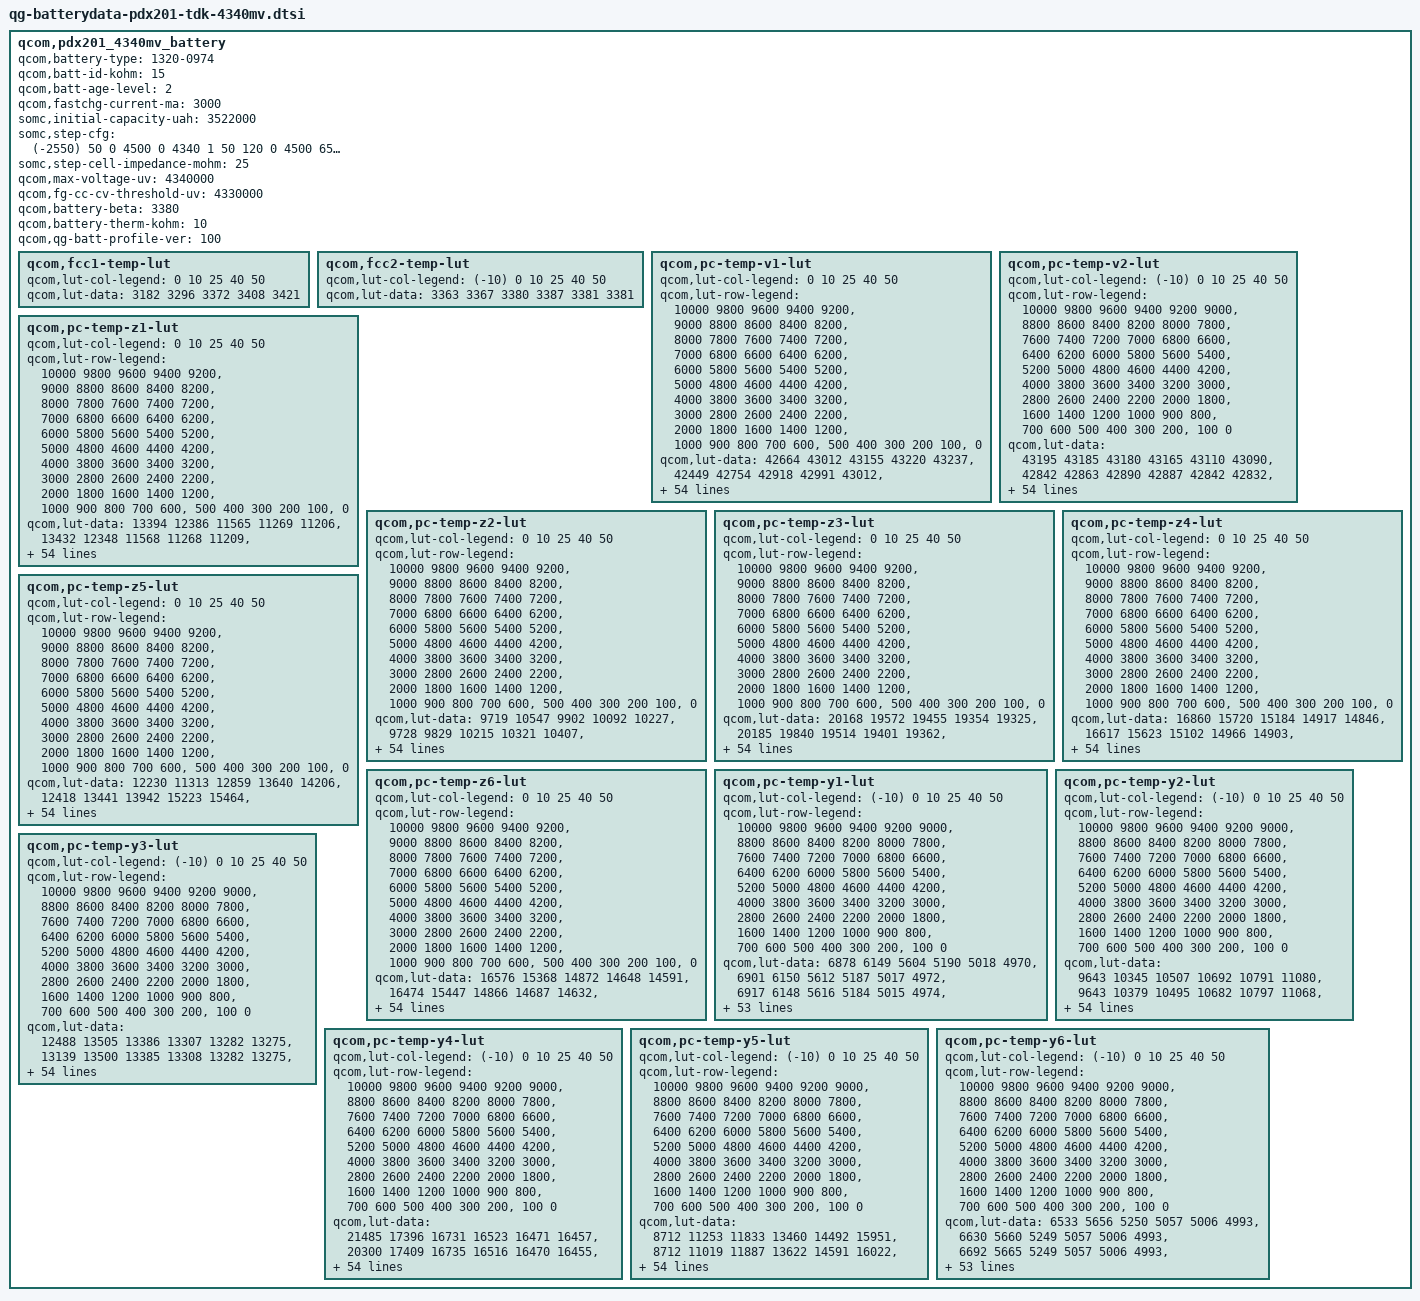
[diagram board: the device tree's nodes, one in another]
// SPDX-License-Identifier: GPL-2.0-only
/*
 * Copyright (c) 2019, The Linux Foundation. All rights reserved.
 */

qcom,pdx201_4340mv_battery {
	/* Added or Modified by SOMC */
	qcom,battery-type = "1320-0974";
	qcom,batt-id-kohm = <15>;
	qcom,batt-age-level = <2>;
	qcom,fastchg-current-ma = <3000>;
	somc,initial-capacity-uah = <3522000>;
	somc,step-cfg = <
		(-2550) 50    0 4500    0 4340 1
		   50  120    0 4500  650 4340 2
		  120  200    0 4100 2050 4340 3
		  120  200 4100 4200 1550 4340 3
		  120  200 4200 4300 1350 4340 3
		  120  200 4300 4500 1000 4340 3
		  200  450    0 4150 3000 4340 3
		  200  450 4150 4200 2400 4340 3
		  200  450 4200 4300 1700 4340 3
		  200  450 4300 4500 1000 4340 3
		  450  550    0 4500 1000 4200 4
		  550 2550    0 4500    0 4200 5
	>;
	somc,step-cell-impedance-mohm = <25>;

	/* Prepared by Qualcomm */
	/* 4176713_SoMC_Amuro2_3389mAh_averaged_MasterSlave_Sept16th2019 */
	qcom,max-voltage-uv = <4340000>;
	qcom,fg-cc-cv-threshold-uv = <4330000>;
	/* qcom,fastchg-current-ma = <1500>; */
	/* qcom,batt-id-kohm = <330>; */
	qcom,battery-beta = <3380>;
	qcom,battery-therm-kohm = <10>;
	/* qcom,battery-type = "4176713_SoMC_Amuro2_3389mAh_averaged_MasterSlave_Sept16th2019"; */
	qcom,qg-batt-profile-ver = <100>;

	qcom,fcc1-temp-lut {
		qcom,lut-col-legend = <0 10 25 40 50>;
		qcom,lut-data = <3182 3296 3372 3408 3421>;
	};

	qcom,fcc2-temp-lut {
		qcom,lut-col-legend = <(-10) 0 10 25 40 50>;
		qcom,lut-data = <3363 3367 3380 3387 3381 3381>;
	};

	qcom,pc-temp-v1-lut {
		qcom,lut-col-legend = <0 10 25 40 50>;
		qcom,lut-row-legend = <10000 9800 9600 9400 9200>,
			<9000 8800 8600 8400 8200>,
			<8000 7800 7600 7400 7200>,
			<7000 6800 6600 6400 6200>,
			<6000 5800 5600 5400 5200>,
			<5000 4800 4600 4400 4200>,
			<4000 3800 3600 3400 3200>,
			<3000 2800 2600 2400 2200>,
			<2000 1800 1600 1400 1200>,
			<1000 900 800 700 600>,
			<500 400 300 200 100>,
			<0>;
		qcom,lut-data = <42664 43012 43155 43220 43237>,
			<42449 42754 42918 42991 43012>,
			<42241 42522 42686 42758 42783>,
			<42043 42306 42457 42528 42557>,
			<41852 42097 42233 42304 42335>,
			<41663 41895 42014 42083 42115>,
			<41475 41700 41803 41866 41895>,
			<41292 41503 41596 41652 41677>,
			<41129 41309 41392 41442 41463>,
			<40988 41126 41188 41228 41254>,
			<40820 40976 40999 41023 41049>,
			<40536 40825 40839 40843 40850>,
			<40184 40598 40677 40678 40655>,
			<39954 40256 40451 40497 40468>,
			<39828 39983 40158 40280 40284>,
			<39729 39857 39944 40071 40107>,
			<39625 39765 39832 39908 39941>,
			<39525 39660 39738 39768 39784>,
			<39422 39544 39614 39622 39627>,
			<39308 39419 39466 39474 39474>,
			<39188 39275 39295 39314 39315>,
			<39071 39115 39059 39115 39127>,
			<38957 38949 38824 38892 38916>,
			<38845 38756 38685 38729 38747>,
			<38733 38589 38592 38617 38627>,
			<38617 38498 38510 38522 38523>,
			<38518 38437 38432 38427 38425>,
			<38442 38384 38361 38339 38335>,
			<38378 38332 38293 38260 38252>,
			<38329 38287 38228 38187 38175>,
			<38290 38247 38173 38123 38106>,
			<38260 38210 38125 38068 38045>,
			<38233 38177 38083 38019 37991>,
			<38211 38146 38046 37974 37940>,
			<38189 38119 38015 37936 37896>,
			<38165 38088 37981 37895 37850>,
			<38139 38060 37946 37848 37791>,
			<38101 38023 37906 37795 37724>,
			<38036 37959 37846 37728 37651>,
			<37951 37864 37753 37643 37571>,
			<37856 37762 37648 37545 37481>,
			<37741 37652 37537 37435 37370>,
			<37609 37526 37412 37309 37241>,
			<37461 37374 37260 37158 37089>,
			<37338 37251 37134 37032 36967>,
			<37270 37175 37060 36959 36898>,
			<37247 37153 37042 36943 36880>,
			<37227 37137 37026 36929 36866>,
			<37199 37119 37008 36909 36843>,
			<37100 37042 36934 36814 36732>,
			<36794 36750 36634 36502 36409>,
			<36348 36307 36201 36068 35972>,
			<35782 35742 35642 35506 35408>,
			<35020 34982 34883 34745 34644>,
			<33823 33804 33720 33575 33459>,
			<30000 30000 30000 30000 30000>;
	};

	qcom,pc-temp-v2-lut {
		qcom,lut-col-legend = <(-10) 0 10 25 40 50>;
		qcom,lut-row-legend = <10000 9800 9600 9400 9200 9000>,
			<8800 8600 8400 8200 8000 7800>,
			<7600 7400 7200 7000 6800 6600>,
			<6400 6200 6000 5800 5600 5400>,
			<5200 5000 4800 4600 4400 4200>,
			<4000 3800 3600 3400 3200 3000>,
			<2800 2600 2400 2200 2000 1800>,
			<1600 1400 1200 1000 900 800>,
			<700 600 500 400 300 200>,
			<100 0>;
		qcom,lut-data = <43195 43185 43180 43165 43110 43090>,
			<42842 42863 42890 42887 42842 42832>,
			<42534 42568 42620 42626 42588 42585>,
			<42279 42308 42373 42383 42350 42350>,
			<42075 42077 42148 42159 42127 42128>,
			<41870 41859 41932 41942 41910 41910>,
			<41613 41644 41718 41726 41694 41694>,
			<41359 41439 41510 41514 41482 41481>,
			<41212 41249 41307 41303 41272 41273>,
			<41139 41081 41104 41090 41064 41068>,
			<41042 40899 40911 40892 40865 40867>,
			<40706 40675 40742 40728 40685 40673>,
			<40193 40423 40576 40571 40512 40484>,
			<39879 40168 40352 40362 40325 40302>,
			<39689 39893 40037 40077 40118 40124>,
			<39535 39658 39773 39846 39927 39953>,
			<39408 39506 39629 39727 39774 39792>,
			<39295 39384 39514 39632 39634 39635>,
			<39121 39242 39365 39495 39475 39470>,
			<38806 39076 39175 39309 39295 39295>,
			<38522 38913 38991 39115 39110 39116>,
			<38346 38766 38835 38918 38915 38922>,
			<38185 38627 38692 38729 38725 38731>,
			<38093 38501 38567 38585 38580 38585>,
			<38044 38388 38453 38471 38467 38470>,
			<38003 38275 38352 38372 38369 38370>,
			<37960 38137 38262 38280 38276 38277>,
			<37919 37994 38180 38196 38191 38191>,
			<37879 37917 38100 38120 38114 38112>,
			<37842 37883 38023 38050 38044 38039>,
			<37805 37854 37952 37986 37980 37973>,
			<37768 37820 37889 37928 37922 37915>,
			<37729 37784 37832 37873 37867 37860>,
			<37690 37748 37785 37817 37805 37794>,
			<37651 37713 37748 37761 37734 37714>,
			<37609 37674 37710 37704 37657 37626>,
			<37565 37632 37665 37639 37570 37527>,
			<37517 37586 37615 37572 37479 37422>,
			<37458 37530 37556 37503 37401 37337>,
			<37385 37458 37487 37436 37338 37271>,
			<37302 37375 37408 37360 37268 37199>,
			<37215 37278 37310 37264 37174 37106>,
			<37125 37165 37193 37150 37061 36994>,
			<37045 37042 37052 37004 36913 36852>,
			<36969 36932 36941 36905 36827 36770>,
			<36894 36858 36886 36863 36801 36743>,
			<36852 36830 36869 36851 36786 36727>,
			<36801 36791 36844 36829 36763 36704>,
			<36729 36738 36803 36792 36719 36661>,
			<36590 36620 36699 36689 36575 36497>,
			<36318 36357 36399 36373 36229 36135>,
			<35888 35907 35925 35907 35749 35650>,
			<35284 35308 35316 35316 35131 35030>,
			<34428 34482 34494 34518 34291 34187>,
			<33127 33280 33344 33323 33065 32948>,
			<29545 29527 29519 29517 29522 29610>;
	};

	qcom,pc-temp-z1-lut {
		qcom,lut-col-legend = <0 10 25 40 50>;
		qcom,lut-row-legend = <10000 9800 9600 9400 9200>,
			<9000 8800 8600 8400 8200>,
			<8000 7800 7600 7400 7200>,
			<7000 6800 6600 6400 6200>,
			<6000 5800 5600 5400 5200>,
			<5000 4800 4600 4400 4200>,
			<4000 3800 3600 3400 3200>,
			<3000 2800 2600 2400 2200>,
			<2000 1800 1600 1400 1200>,
			<1000 900 800 700 600>,
			<500 400 300 200 100>,
			<0>;
		qcom,lut-data = <13394 12386 11565 11269 11206>,
			<13432 12348 11568 11268 11209>,
			<13451 12342 11569 11273 11213>,
			<13453 12340 11566 11276 11216>,
			<13454 12340 11561 11276 11218>,
			<13450 12343 11559 11276 11220>,
			<13439 12346 11559 11277 11221>,
			<13427 12345 11561 11278 11222>,
			<13424 12341 11562 11279 11222>,
			<13427 12336 11565 11281 11222>,
			<13428 12328 11566 11283 11223>,
			<13411 12316 11561 11282 11223>,
			<13379 12304 11552 11278 11223>,
			<13367 12288 11545 11277 11223>,
			<13368 12279 11538 11277 11224>,
			<13371 12283 11535 11277 11225>,
			<13371 12291 11542 11278 11226>,
			<13367 12299 11551 11281 11227>,
			<13364 12308 11555 11282 11228>,
			<13366 12316 11557 11283 11228>,
			<13372 12322 11559 11283 11228>,
			<13380 12326 11561 11284 11229>,
			<13393 12330 11562 11285 11230>,
			<13405 12334 11565 11286 11232>,
			<13404 12337 11568 11288 11234>,
			<13390 12343 11571 11291 11236>,
			<13381 12352 11575 11294 11237>,
			<13382 12357 11578 11296 11239>,
			<13384 12358 11581 11297 11241>,
			<13388 12357 11584 11299 11242>,
			<13417 12361 11587 11300 11244>,
			<13448 12373 11590 11303 11245>,
			<13446 12383 11592 11305 11247>,
			<13422 12385 11595 11307 11248>,
			<13406 12386 11599 11308 11249>,
			<13409 12389 11602 11309 11249>,
			<13415 12396 11605 11310 11250>,
			<13425 12401 11608 11312 11251>,
			<13459 12403 11610 11312 11251>,
			<13491 12406 11612 11313 11251>,
			<13483 12407 11613 11313 11252>,
			<13444 12406 11614 11313 11252>,
			<13434 12407 11614 11314 11252>,
			<13425 12419 11615 11314 11252>,
			<13401 12423 11619 11315 11253>,
			<13398 12408 11622 11314 11253>,
			<13402 12417 11617 11314 11253>,
			<13398 12413 11617 11314 11253>,
			<13383 12429 11616 11314 11253>,
			<13385 12419 11620 11316 11253>,
			<13413 12427 11623 11317 11255>,
			<13419 12455 11636 11322 11258>,
			<13431 12462 11649 11329 11265>,
			<13481 12509 11675 11342 11272>,
			<13481 12509 11675 11342 11272>,
			<13481 12509 11675 11342 11272>;
	};

	qcom,pc-temp-z2-lut {
		qcom,lut-col-legend = <0 10 25 40 50>;
		qcom,lut-row-legend = <10000 9800 9600 9400 9200>,
			<9000 8800 8600 8400 8200>,
			<8000 7800 7600 7400 7200>,
			<7000 6800 6600 6400 6200>,
			<6000 5800 5600 5400 5200>,
			<5000 4800 4600 4400 4200>,
			<4000 3800 3600 3400 3200>,
			<3000 2800 2600 2400 2200>,
			<2000 1800 1600 1400 1200>,
			<1000 900 800 700 600>,
			<500 400 300 200 100>,
			<0>;
		qcom,lut-data = <9719 10547 9902 10092 10227>,
			<9728 9829 10215 10321 10407>,
			<9741 9792 10392 10782 10930>,
			<9763 9792 10384 10940 11212>,
			<9792 9792 10317 10637 11095>,
			<9808 9794 10274 10326 10933>,
			<9817 9796 10266 10373 10917>,
			<9822 9797 10258 10560 10951>,
			<9822 9797 10202 10634 10969>,
			<9819 9798 10081 10653 10953>,
			<9813 9865 10033 10670 10933>,
			<9797 9956 10062 10559 10940>,
			<9772 9960 10094 10277 10969>,
			<9763 9896 10098 10202 10977>,
			<9765 9852 10095 10447 10714>,
			<9769 9866 10094 10675 10426>,
			<9772 9897 10104 10575 10406>,
			<9775 9921 10117 10315 10413>,
			<9777 9942 10123 10231 10419>,
			<9781 9958 10138 10233 10426>,
			<9786 9968 10150 10234 10431>,
			<9791 9976 10161 10234 10431>,
			<9800 9986 10171 10235 10435>,
			<9809 10005 10173 10239 10446>,
			<9819 10021 10170 10271 10485>,
			<9830 10017 10170 10314 10520>,
			<9838 9999 10193 10354 10491>,
			<9841 9990 10223 10393 10402>,
			<9843 9989 10224 10398 10340>,
			<9844 9990 10207 10359 10301>,
			<9846 9993 10195 10327 10279>,
			<9847 10000 10193 10331 10288>,
			<9849 10007 10192 10348 10319>,
			<9851 10011 10196 10371 10357>,
			<9854 10015 10214 10414 10414>,
			<9858 10018 10230 10459 10466>,
			<9863 10023 10237 10493 10492>,
			<9870 10028 10243 10522 10512>,
			<9881 10037 10257 10536 10535>,
			<9894 10050 10285 10546 10568>,
			<9906 10056 10301 10551 10594>,
			<9919 10059 10297 10537 10599>,
			<9939 10063 10295 10514 10598>,
			<9981 10083 10306 10500 10582>,
			<10205 10202 10366 10516 10608>,
			<10199 10240 10396 10535 10656>,
			<10196 10235 10376 10538 10647>,
			<10195 10229 10394 10545 10635>,
			<10205 10247 10385 10556 10695>,
			<10236 10269 10428 10685 10742>,
			<10235 10279 10459 10566 10475>,
			<10167 10230 10408 10491 10407>,
			<10097 10192 10369 10419 10337>,
			<9900 10160 10305 10396 10284>,
			<9900 10160 10305 10396 10284>,
			<9900 10160 10305 10396 10284>;
	};

	qcom,pc-temp-z3-lut {
		qcom,lut-col-legend = <0 10 25 40 50>;
		qcom,lut-row-legend = <10000 9800 9600 9400 9200>,
			<9000 8800 8600 8400 8200>,
			<8000 7800 7600 7400 7200>,
			<7000 6800 6600 6400 6200>,
			<6000 5800 5600 5400 5200>,
			<5000 4800 4600 4400 4200>,
			<4000 3800 3600 3400 3200>,
			<3000 2800 2600 2400 2200>,
			<2000 1800 1600 1400 1200>,
			<1000 900 800 700 600>,
			<500 400 300 200 100>,
			<0>;
		qcom,lut-data = <20168 19572 19455 19354 19325>,
			<20185 19840 19514 19401 19362>,
			<20187 19863 19556 19434 19383>,
			<20161 19868 19578 19444 19396>,
			<20102 19868 19593 19440 19401>,
			<20056 19850 19597 19436 19403>,
			<20027 19825 19587 19434 19401>,
			<20001 19813 19570 19429 19398>,
			<19961 19804 19556 19425 19395>,
			<19903 19798 19539 19425 19387>,
			<19869 19796 19522 19424 19378>,
			<19913 19795 19493 19410 19374>,
			<20000 19786 19467 19376 19372>,
			<20030 19760 19467 19365 19369>,
			<19996 19730 19476 19381 19351>,
			<19955 19697 19480 19396 19333>,
			<19947 19664 19453 19388 19331>,
			<19949 19654 19421 19368 19330>,
			<19953 19651 19423 19361 19330>,
			<19963 19651 19451 19366 19335>,
			<19980 19665 19479 19372 19340>,
			<19992 19699 19504 19376 19339>,
			<19997 19728 19523 19378 19334>,
			<20002 19752 19521 19378 19332>,
			<20012 19768 19503 19370 19335>,
			<20028 19764 19489 19363 19341>,
			<20037 19745 19484 19374 19349>,
			<20034 19727 19481 19400 19362>,
			<20024 19714 19486 19412 19368>,
			<20014 19704 19505 19415 19369>,
			<20001 19698 19515 19416 19370>,
			<19987 19694 19513 19414 19369>,
			<19976 19693 19510 19407 19365>,
			<19965 19693 19506 19402 19361>,
			<19955 19692 19501 19397 19357>,
			<19948 19692 19496 19393 19353>,
			<19941 19689 19493 19393 19353>,
			<19934 19685 19489 19393 19354>,
			<19927 19682 19487 19391 19354>,
			<19918 19681 19484 19386 19349>,
			<19904 19678 19482 19381 19346>,
			<19883 19671 19478 19374 19345>,
			<19858 19661 19473 19368 19346>,
			<19820 19644 19467 19365 19347>,
			<19685 19579 19447 19360 19342>,
			<19674 19558 19433 19356 19331>,
			<19668 19557 19426 19346 19329>,
			<19662 19553 19428 19344 19327>,
			<19649 19539 19419 19339 19321>,
			<19636 19535 19406 19332 19327>,
			<19636 19528 19408 19344 19347>,
			<19635 19534 19409 19352 19350>,
			<19595 19528 19403 19359 19354>,
			<19497 19493 19401 19357 19360>,
			<19497 19493 19401 19357 19360>,
			<19497 19493 19401 19357 19360>;
	};

	qcom,pc-temp-z4-lut {
		qcom,lut-col-legend = <0 10 25 40 50>;
		qcom,lut-row-legend = <10000 9800 9600 9400 9200>,
			<9000 8800 8600 8400 8200>,
			<8000 7800 7600 7400 7200>,
			<7000 6800 6600 6400 6200>,
			<6000 5800 5600 5400 5200>,
			<5000 4800 4600 4400 4200>,
			<4000 3800 3600 3400 3200>,
			<3000 2800 2600 2400 2200>,
			<2000 1800 1600 1400 1200>,
			<1000 900 800 700 600>,
			<500 400 300 200 100>,
			<0>;
		qcom,lut-data = <16860 15720 15184 14917 14846>,
			<16617 15623 15102 14966 14903>,
			<16413 15497 15027 14904 14864>,
			<16250 15352 14959 14861 14822>,
			<16112 15245 14896 14838 14791>,
			<15999 15173 14849 14820 14764>,
			<15910 15116 14811 14799 14747>,
			<15832 15072 14785 14771 14736>,
			<15747 15040 14785 14753 14728>,
			<15660 14997 14804 14741 14723>,
			<15574 14899 14810 14733 14719>,
			<15490 14799 14800 14733 14711>,
			<15409 14795 14789 14742 14699>,
			<15341 14860 14783 14741 14691>,
			<15287 14905 14779 14715 14699>,
			<15237 14902 14778 14691 14708>,
			<15182 14893 14780 14691 14703>,
			<15122 14886 14783 14699 14691>,
			<15074 14875 14775 14701 14686>,
			<15040 14865 14743 14699 14687>,
			<15011 14859 14728 14698 14689>,
			<14999 14854 14788 14737 14720>,
			<14995 14855 14866 14826 14806>,
			<14993 14902 14880 14856 14842>,
			<14995 14952 14882 14855 14834>,
			<15005 14957 14882 14853 14819>,
			<15016 14955 14873 14832 14797>,
			<15026 14952 14856 14785 14766>,
			<15036 14947 14834 14753 14741>,
			<15038 14939 14801 14733 14723>,
			<15037 14930 14779 14719 14709>,
			<15035 14918 14769 14710 14698>,
			<15032 14907 14763 14704 14689>,
			<15024 14897 14761 14702 14686>,
			<15016 14890 14761 14703 14689>,
			<15007 14887 14760 14703 14693>,
			<14998 14886 14763 14709 14706>,
			<14993 14885 14769 14721 14727>,
			<14991 14890 14777 14730 14732>,
			<14989 14901 14790 14740 14730>,
			<14987 14905 14797 14746 14728>,
			<14984 14896 14794 14745 14720>,
			<14975 14885 14788 14744 14713>,
			<14945 14872 14786 14749 14716>,
			<14853 14816 14763 14740 14713>,
			<14845 14786 14735 14715 14699>,
			<14838 14778 14728 14707 14684>,
			<14830 14773 14713 14689 14664>,
			<14823 14772 14712 14683 14659>,
			<14824 14772 14730 14707 14674>,
			<14842 14792 14746 14711 14664>,
			<14857 14789 14746 14703 14661>,
			<14896 14791 14750 14695 14658>,
			<14998 14813 14746 14693 14651>,
			<14998 14813 14746 14693 14651>,
			<14998 14813 14746 14693 14651>;
	};

	qcom,pc-temp-z5-lut {
		qcom,lut-col-legend = <0 10 25 40 50>;
		qcom,lut-row-legend = <10000 9800 9600 9400 9200>,
			<9000 8800 8600 8400 8200>,
			<8000 7800 7600 7400 7200>,
			<7000 6800 6600 6400 6200>,
			<6000 5800 5600 5400 5200>,
			<5000 4800 4600 4400 4200>,
			<4000 3800 3600 3400 3200>,
			<3000 2800 2600 2400 2200>,
			<2000 1800 1600 1400 1200>,
			<1000 900 800 700 600>,
			<500 400 300 200 100>,
			<0>;
		qcom,lut-data = <12230 11313 12859 13640 14206>,
			<12418 13441 13942 15223 15464>,
			<12524 14084 15017 16554 16320>,
			<12534 14432 16121 17085 17013>,
			<12528 14559 17309 17163 17839>,
			<12532 14589 18198 17199 18771>,
			<12554 14617 18925 17517 19585>,
			<12572 14711 19415 18401 20476>,
			<12537 14972 19141 19225 20844>,
			<12392 15396 18029 20128 20367>,
			<12291 17421 17228 20740 19764>,
			<12757 19934 16454 19582 20133>,
			<13684 20100 15764 16641 21605>,
			<14025 18459 15925 15877 22187>,
			<13990 16908 16752 19382 19564>,
			<13949 16116 17140 22694 16660>,
			<14067 15524 16003 21669 16563>,
			<14654 15440 14598 18822 17237>,
			<15417 15912 15004 18101 18205>,
			<16397 16767 17675 20040 20357>,
			<17741 18815 21205 21821 22321>,
			<19037 22666 27615 21732 21635>,
			<20188 26173 33720 21155 18803>,
			<21441 29983 32661 20167 16733>,
			<23290 32730 25146 17370 15484>,
			<25972 31539 19889 15170 14754>,
			<27487 26745 18202 15579 15002>,
			<27260 23260 17217 16928 15965>,
			<26671 21663 17528 18412 17048>,
			<25986 20656 19407 20236 18288>,
			<24969 20529 21146 22060 19709>,
			<23918 20551 22318 23633 21435>,
			<23202 20591 23213 25037 23365>,
			<22583 20946 23596 25879 24402>,
			<22255 21565 23827 26470 25041>,
			<22272 21895 23909 26755 25304>,
			<22423 22065 23554 26326 24571>,
			<22630 22183 22875 25231 22991>,
			<23277 22273 22200 23947 21459>,
			<23890 22345 21415 21475 19565>,
			<23727 22346 20815 19321 18316>,
			<23035 22078 20325 18203 18168>,
			<22959 21856 19924 17360 18087>,
			<23407 21721 19437 16513 17665>,
			<25243 22222 19942 16574 16772>,
			<24237 22828 20372 17376 16390>,
			<23636 23007 19815 16590 16942>,
			<23284 22949 20965 17307 18400>,
			<22757 21535 20204 17532 18654>,
			<22280 21692 17976 15325 16724>,
			<21477 19374 16639 14976 18291>,
			<18852 19105 16336 15448 18696>,
			<15781 17795 15676 16043 19430>,
			<13286 15114 15363 15862 21486>,
			<13286 15114 15363 15862 21486>,
			<13286 15114 15363 15862 21486>;
	};

	qcom,pc-temp-z6-lut {
		qcom,lut-col-legend = <0 10 25 40 50>;
		qcom,lut-row-legend = <10000 9800 9600 9400 9200>,
			<9000 8800 8600 8400 8200>,
			<8000 7800 7600 7400 7200>,
			<7000 6800 6600 6400 6200>,
			<6000 5800 5600 5400 5200>,
			<5000 4800 4600 4400 4200>,
			<4000 3800 3600 3400 3200>,
			<3000 2800 2600 2400 2200>,
			<2000 1800 1600 1400 1200>,
			<1000 900 800 700 600>,
			<500 400 300 200 100>,
			<0>;
		qcom,lut-data = <16576 15368 14872 14648 14591>,
			<16474 15447 14866 14687 14632>,
			<16376 15425 14857 14683 14628>,
			<16280 15354 14844 14677 14623>,
			<16188 15293 14823 14667 14615>,
			<16113 15249 14802 14655 14603>,
			<16059 15212 14779 14642 14595>,
			<16009 15186 14760 14628 14588>,
			<15946 15167 14753 14619 14582>,
			<15867 15143 14750 14615 14576>,
			<15814 15096 14744 14611 14569>,
			<15799 15050 14723 14601 14563>,
			<15791 15043 14702 14586 14557>,
			<15775 15047 14700 14578 14551>,
			<15733 15050 14701 14576 14545>,
			<15686 15039 14701 14574 14539>,
			<15657 15017 14689 14569 14533>,
			<15634 15007 14674 14561 14528>,
			<15621 15003 14673 14558 14526>,
			<15619 15001 14675 14559 14527>,
			<15618 15006 14680 14562 14531>,
			<15618 15021 14718 14582 14546>,
			<15620 15040 14764 14621 14581>,
			<15625 15074 14769 14634 14594>,
			<15632 15104 14762 14631 14593>,
			<15647 15104 14755 14626 14590>,
			<15657 15095 14748 14622 14586>,
			<15658 15086 14741 14616 14579>,
			<15658 15078 14735 14610 14573>,
			<15656 15070 14730 14604 14566>,
			<15651 15064 14726 14597 14560>,
			<15644 15057 14721 14591 14553>,
			<15638 15053 14717 14586 14547>,
			<15631 15050 14714 14582 14544>,
			<15625 15048 14711 14579 14543>,
			<15620 15047 14709 14577 14542>,
			<15616 15046 14710 14580 14546>,
			<15612 15046 14710 14585 14556>,
			<15609 15048 14712 14587 14558>,
			<15605 15054 14716 14588 14556>,
			<15599 15056 14719 14589 14552>,
			<15588 15049 14716 14585 14548>,
			<15571 15040 14711 14581 14546>,
			<15538 15028 14707 14581 14548>,
			<15431 14974 14687 14575 14544>,
			<15422 14951 14668 14562 14532>,
			<15414 14947 14661 14553 14525>,
			<15407 14942 14656 14545 14514>,
			<15401 14935 14650 14539 14509>,
			<15401 14936 14652 14546 14518>,
			<15418 14945 14660 14555 14526>,
			<15434 14954 14664 14556 14527>,
			<15452 14961 14666 14558 14529>,
			<15479 14972 14669 14559 14531>,
			<15479 14972 14669 14559 14531>,
			<15479 14972 14669 14559 14531>;
	};

	qcom,pc-temp-y1-lut {
		qcom,lut-col-legend = <(-10) 0 10 25 40 50>;
		qcom,lut-row-legend = <10000 9800 9600 9400 9200 9000>,
			<8800 8600 8400 8200 8000 7800>,
			<7600 7400 7200 7000 6800 6600>,
			<6400 6200 6000 5800 5600 5400>,
			<5200 5000 4800 4600 4400 4200>,
			<4000 3800 3600 3400 3200 3000>,
			<2800 2600 2400 2200 2000 1800>,
			<1600 1400 1200 1000 900 800>,
			<700 600 500 400 300 200>,
			<100 0>;
		qcom,lut-data = <6878 6149 5604 5190 5018 4970>,
			<6901 6150 5612 5187 5017 4972>,
			<6917 6148 5616 5184 5015 4974>,
			<6926 6145 5616 5181 5014 4975>,
			<6930 6141 5615 5178 5013 4975>,
			<6931 6140 5614 5176 5012 4975>,
			<6925 6139 5610 5174 5011 4975>,
			<6915 6138 5604 5172 5010 4973>,
			<6920 6138 5603 5171 5010 4973>,
			<6951 6137 5602 5168 5009 4974>,
			<6973 6137 5601 5167 5008 4974>,
			<6956 6138 5598 5166 5008 4973>,
			<6925 6142 5593 5166 5008 4972>,
			<6920 6146 5593 5167 5008 4972>,
			<6932 6153 5601 5169 5010 4974>,
			<6940 6158 5607 5170 5011 4975>,
			<6928 6164 5606 5170 5010 4975>,
			<6907 6174 5605 5169 5009 4975>,
			<6904 6175 5605 5169 5009 4975>,
			<6927 6172 5605 5170 5010 4975>,
			<6946 6170 5605 5172 5010 4975>,
			<6933 6171 5605 5174 5011 4976>,
			<6904 6172 5607 5177 5012 4977>,
			<6892 6174 5609 5178 5013 4977>,
			<6889 6181 5613 5180 5014 4977>,
			<6887 6186 5617 5182 5015 4978>,
			<6891 6179 5617 5184 5016 4978>,
			<6902 6167 5615 5186 5017 4980>,
			<6906 6165 5617 5189 5018 4981>,
			<6900 6172 5620 5192 5020 4983>,
			<6893 6178 5624 5195 5021 4984>,
			<6886 6179 5634 5199 5022 4985>,
			<6874 6180 5645 5203 5024 4986>,
			<6869 6179 5650 5206 5025 4986>,
			<6867 6175 5652 5207 5027 4988>,
			<6865 6171 5655 5209 5028 4989>,
			<6863 6178 5659 5214 5029 4990>,
			<6861 6193 5662 5218 5030 4990>,
			<6861 6196 5666 5219 5031 4991>,
			<6866 6182 5671 5219 5031 4991>,
			<6873 6169 5675 5219 5031 4992>,
			<6877 6167 5672 5220 5032 4992>,
			<6879 6165 5671 5221 5032 4991>,
			<6864 6179 5670 5224 5033 4991>,
			<6855 6186 5675 5227 5032 4991>,
			<6886 6181 5677 5226 5032 4992>,
			<6860 6195 5677 5227 5034 4992>,
			<6865 6179 5670 5227 5034 4992>,
			<6881 6174 5679 5227 5033 4993>,
			<6872 6180 5685 5230 5034 4994>,
			<6917 6200 5689 5235 5036 4995>,
			<6947 6235 5706 5243 5040 4998>,
			<6956 6268 5719 5254 5045 5002>,
			<7015 6278 5737 5267 5052 5006>,
			<7015 6278 5737 5267 5052 5006>,
			<7015 6278 5737 5267 5052 5006>;
	};

	qcom,pc-temp-y2-lut {
		qcom,lut-col-legend = <(-10) 0 10 25 40 50>;
		qcom,lut-row-legend = <10000 9800 9600 9400 9200 9000>,
			<8800 8600 8400 8200 8000 7800>,
			<7600 7400 7200 7000 6800 6600>,
			<6400 6200 6000 5800 5600 5400>,
			<5200 5000 4800 4600 4400 4200>,
			<4000 3800 3600 3400 3200 3000>,
			<2800 2600 2400 2200 2000 1800>,
			<1600 1400 1200 1000 900 800>,
			<700 600 500 400 300 200>,
			<100 0>;
		qcom,lut-data = <9643 10345 10507 10692 10791 11080>,
			<9643 10379 10495 10682 10797 11068>,
			<9962 10393 10482 10669 10796 11048>,
			<10290 10391 10470 10656 10791 11025>,
			<10490 10378 10459 10645 10787 11003>,
			<10560 10359 10448 10640 10784 10986>,
			<10429 10319 10436 10636 10783 10971>,
			<10209 10271 10425 10631 10780 10956>,
			<10178 10275 10419 10633 10776 10952>,
			<10304 10369 10413 10642 10767 10952>,
			<10436 10459 10411 10650 10762 10954>,
			<10525 10505 10424 10656 10772 10968>,
			<10603 10539 10452 10662 10791 10990>,
			<10633 10547 10490 10678 10799 10994>,
			<10636 10548 10553 10718 10802 10991>,
			<10620 10549 10597 10754 10807 10990>,
			<10438 10572 10606 10772 10857 10992>,
			<10111 10619 10613 10785 10939 10998>,
			<9994 10654 10625 10795 10976 11012>,
			<9973 10677 10650 10801 10995 11050>,
			<9955 10703 10680 10811 11005 11084>,
			<9869 10745 10713 10839 11002 11100>,
			<9716 10792 10749 10882 11000 11114>,
			<9662 10791 10778 10916 11014 11130>,
			<9658 10682 10802 10945 11061 11153>,
			<9656 10590 10826 10975 11101 11168>,
			<9655 10604 10860 11010 11123 11167>,
			<9654 10639 10892 11046 11145 11163>,
			<9654 10647 10899 11075 11158 11177>,
			<9654 10599 10892 11101 11169 11212>,
			<9654 10538 10884 11123 11185 11255>,
			<9654 10419 10873 11151 11237 11309>,
			<9654 10220 10855 11178 11320 11376>,
			<9653 10129 10827 11181 11356 11439>,
			<9653 9936 10763 11161 11362 11509>,
			<9653 9740 10695 11139 11359 11553>,
			<9653 9702 10648 11123 11370 11568>,
			<9653 9686 10608 11107 11395 11581>,
			<9653 9677 10571 11091 11409 11584>,
			<9653 9671 10538 11076 11431 11574>,
			<9653 9666 10507 11058 11445 11559>,
			<9653 9663 10477 11033 11403 11523>,
			<9653 9661 10448 11005 11347 11488>,
			<9653 9658 10413 10974 11343 11509>,
			<9653 9657 10378 10949 11309 11478>,
			<9652 9657 10403 10955 11281 11372>,
			<9652 9657 10400 10963 11326 11410>,
			<9652 9656 10385 10970 11300 11329>,
			<9652 9656 10366 10971 11258 11231>,
			<9652 9655 10354 10928 11200 11145>,
			<9652 9654 10329 10912 11148 11150>,
			<9651 9654 10284 10842 11067 11042>,
			<9650 9653 10239 10803 11014 10964>,
			<9649 9651 10193 10733 10908 10867>,
			<9649 9651 10193 10733 10908 10867>,
			<9649 9651 10193 10733 10908 10867>;
	};

	qcom,pc-temp-y3-lut {
		qcom,lut-col-legend = <(-10) 0 10 25 40 50>;
		qcom,lut-row-legend = <10000 9800 9600 9400 9200 9000>,
			<8800 8600 8400 8200 8000 7800>,
			<7600 7400 7200 7000 6800 6600>,
			<6400 6200 6000 5800 5600 5400>,
			<5200 5000 4800 4600 4400 4200>,
			<4000 3800 3600 3400 3200 3000>,
			<2800 2600 2400 2200 2000 1800>,
			<1600 1400 1200 1000 900 800>,
			<700 600 500 400 300 200>,
			<100 0>;
		qcom,lut-data = <12488 13505 13386 13307 13282 13275>,
			<13139 13500 13385 13308 13282 13275>,
			<13568 13501 13386 13309 13282 13275>,
			<13820 13507 13387 13310 13283 13276>,
			<13940 13516 13388 13310 13283 13277>,
			<13971 13528 13389 13311 13283 13277>,
			<13811 13555 13393 13310 13284 13278>,
			<13543 13587 13398 13310 13284 13278>,
			<13499 13586 13400 13309 13284 13279>,
			<13608 13541 13401 13308 13283 13278>,
			<13692 13509 13402 13307 13283 13278>,
			<13688 13515 13408 13310 13285 13278>,
			<13661 13525 13416 13316 13288 13277>,
			<13627 13526 13416 13317 13288 13278>,
			<13552 13511 13403 13318 13288 13281>,
			<13492 13493 13394 13318 13288 13283>,
			<13484 13481 13397 13322 13290 13282>,
			<13487 13469 13404 13327 13294 13281>,
			<13491 13457 13403 13328 13295 13282>,
			<13497 13447 13389 13327 13295 13283>,
			<13505 13437 13374 13325 13294 13285>,
			<13522 13424 13366 13318 13290 13282>,
			<13559 13412 13359 13307 13283 13277>,
			<13607 13401 13354 13302 13281 13276>,
			<13716 13389 13350 13300 13282 13276>,
			<13845 13381 13347 13299 13283 13276>,
			<13949 13376 13346 13299 13282 13276>,
			<14047 13371 13345 13299 13281 13276>,
			<14134 13372 13344 13300 13281 13276>,
			<14211 13393 13341 13302 13282 13276>,
			<14279 13413 13339 13303 13284 13276>,
			<14341 13415 13340 13303 13284 13277>,
			<14396 13413 13342 13303 13285 13278>,
			<14450 13413 13346 13302 13285 13278>,
			<14502 13421 13353 13302 13283 13278>,
			<14554 13432 13361 13301 13281 13277>,
			<14612 13445 13367 13302 13280 13276>,
			<14673 13465 13372 13302 13278 13273>,
			<14734 13488 13376 13303 13278 13273>,
			<14791 13514 13380 13303 13279 13273>,
			<14850 13546 13384 13303 13281 13274>,
			<14914 13592 13387 13303 13281 13274>,
			<14986 13656 13390 13304 13281 13274>,
			<15075 13733 13393 13304 13280 13274>,
			<15178 13835 13398 13307 13280 13274>,
			<15191 13863 13388 13304 13284 13275>,
			<15072 13815 13392 13307 13285 13277>,
			<15213 13894 13397 13306 13287 13281>,
			<15354 13998 13406 13311 13290 13287>,
			<15514 14108 13422 13315 13290 13284>,
			<15709 14218 13419 13311 13290 13282>,
			<16054 14394 13431 13316 13292 13283>,
			<16676 14739 13454 13326 13294 13287>,
			<17416 15179 13489 13332 13298 13290>,
			<17416 15179 13489 13332 13298 13290>,
			<17416 15179 13489 13332 13298 13290>;
	};

	qcom,pc-temp-y4-lut {
		qcom,lut-col-legend = <(-10) 0 10 25 40 50>;
		qcom,lut-row-legend = <10000 9800 9600 9400 9200 9000>,
			<8800 8600 8400 8200 8000 7800>,
			<7600 7400 7200 7000 6800 6600>,
			<6400 6200 6000 5800 5600 5400>,
			<5200 5000 4800 4600 4400 4200>,
			<4000 3800 3600 3400 3200 3000>,
			<2800 2600 2400 2200 2000 1800>,
			<1600 1400 1200 1000 900 800>,
			<700 600 500 400 300 200>,
			<100 0>;
		qcom,lut-data = <21485 17396 16731 16523 16471 16457>,
			<20300 17409 16735 16516 16470 16455>,
			<19510 17415 16739 16513 16469 16455>,
			<19038 17415 16741 16513 16470 16456>,
			<18809 17412 16743 16516 16472 16457>,
			<18748 17407 16745 16519 16474 16458>,
			<19037 17363 16746 16526 16478 16461>,
			<19522 17296 16748 16534 16482 16463>,
			<19623 17312 16752 16544 16488 16467>,
			<19549 17498 16758 16555 16495 16473>,
			<19423 17631 16767 16567 16503 16479>,
			<18993 17582 16816 16580 16512 16487>,
			<18364 17477 16885 16592 16522 16496>,
			<18218 17396 16894 16599 16532 16502>,
			<18287 17310 16867 16603 16543 16507>,
			<18342 17260 16849 16609 16553 16513>,
			<18329 17297 16861 16636 16564 16526>,
			<18288 17370 16881 16673 16575 16543>,
			<18179 17382 16875 16678 16580 16550>,
			<17736 17321 16810 16666 16585 16555>,
			<17340 17250 16750 16648 16585 16557>,
			<17206 17209 16724 16598 16551 16529>,
			<17091 17173 16706 16537 16496 16483>,
			<17064 17129 16702 16524 16479 16468>,
			<17084 17072 16703 16524 16474 16464>,
			<17107 17007 16704 16526 16473 16463>,
			<17121 16899 16708 16529 16476 16465>,
			<17132 16757 16715 16536 16484 16471>,
			<17142 16717 16713 16543 16492 16478>,
			<17152 16750 16693 16550 16501 16486>,
			<17161 16800 16672 16559 16510 16496>,
			<17172 16857 16656 16571 16524 16509>,
			<17183 16925 16641 16584 16538 16520>,
			<17196 16979 16641 16585 16540 16522>,
			<17214 17031 16671 16576 16533 16510>,
			<17228 17075 16703 16566 16523 16497>,
			<17231 17102 16721 16556 16509 16486>,
			<17233 17121 16736 16547 16494 16477>,
			<17232 17133 16748 16546 16492 16475>,
			<17219 17143 16759 16550 16497 16479>,
			<17202 17148 16769 16554 16502 16483>,
			<17188 17147 16781 16557 16502 16483>,
			<17177 17143 16793 16558 16501 16483>,
			<17188 17138 16803 16557 16494 16476>,
			<17231 17141 16811 16555 16492 16474>,
			<17270 17124 16769 16550 16501 16487>,
			<17252 17125 16776 16559 16506 16491>,
			<17304 17194 16806 16576 16514 16495>,
			<17348 17275 16863 16592 16524 16509>,
			<17366 17319 16907 16597 16516 16495>,
			<17365 17320 16882 16574 16497 16477>,
			<17443 17318 16895 16586 16505 16484>,
			<17760 17361 16950 16623 16529 16507>,
			<18387 17588 17048 16701 16594 16575>,
			<18387 17588 17048 16701 16594 16575>,
			<18387 17588 17048 16701 16594 16575>;
	};

	qcom,pc-temp-y5-lut {
		qcom,lut-col-legend = <(-10) 0 10 25 40 50>;
		qcom,lut-row-legend = <10000 9800 9600 9400 9200 9000>,
			<8800 8600 8400 8200 8000 7800>,
			<7600 7400 7200 7000 6800 6600>,
			<6400 6200 6000 5800 5600 5400>,
			<5200 5000 4800 4600 4400 4200>,
			<4000 3800 3600 3400 3200 3000>,
			<2800 2600 2400 2200 2000 1800>,
			<1600 1400 1200 1000 900 800>,
			<700 600 500 400 300 200>,
			<100 0>;
		qcom,lut-data = <8712 11253 11833 13460 14492 15951>,
			<8712 11019 11887 13622 14591 16022>,
			<9912 10927 11932 13669 14590 16004>,
			<11184 10947 11968 13626 14511 15916>,
			<11935 11052 11993 13519 14379 15775>,
			<12190 11212 12008 13373 14214 15598>,
			<11639 11672 12110 13157 13991 15374>,
			<10715 12265 12252 12877 13705 15092>,
			<10697 12256 12239 12589 13387 14758>,
			<11950 11431 12113 12247 12977 14336>,
			<12994 10840 12034 12074 12758 13901>,
			<13086 11609 12330 12270 12868 13402>,
			<12974 12975 12860 12588 13049 12961>,
			<12919 13260 13104 12681 13048 12951>,
			<12740 12919 13215 12697 12823 13351>,
			<12648 12636 13352 12725 12669 13625>,
			<13186 12614 13878 12953 12853 13415>,
			<14195 12666 14565 13438 13289 13069>,
			<14759 12777 14671 14228 13898 13185>,
			<14791 13027 14422 15799 15001 14356>,
			<14654 13329 14139 16726 15671 15297>,
			<13662 13582 13917 15890 15342 15466>,
			<11658 13864 13717 14452 14808 15581>,
			<10982 14425 13614 13898 14760 15721>,
			<10997 15961 13543 13624 15097 16010>,
			<11024 17104 13519 13509 15320 16198>,
			<11053 16027 13695 13496 14896 15873>,
			<11094 13719 14123 13503 14166 15237>,
			<11144 12956 14796 13690 14049 14876>,
			<11232 13141 16178 14210 14427 14621>,
			<11319 13311 17059 14698 14836 14507>,
			<11363 12988 16878 15199 15103 14641>,
			<11395 12372 16509 15806 15355 14921>,
			<11422 12120 16226 16210 15588 15262>,
			<11439 11775 15836 16713 15952 15985>,
			<11461 11454 15419 16976 16163 16468>,
			<11529 11440 15069 16899 15764 16126>,
			<11655 11447 14737 16708 15030 15456>,
			<11703 11447 14461 16416 14875 15060>,
			<11659 11418 14201 15870 15088 14683>,
			<11592 11390 13929 15473 15239 14407>,
			<11507 11395 13576 15330 15107 14193>,
			<11399 11408 13214 15252 14878 14041>,
			<11363 11326 12984 15048 14734 14687>,
			<11321 11242 12813 15418 14911 14903>,
			<11298 11315 13080 14947 15290 13667>,
			<11348 11312 13261 15291 14788 13661>,
			<11414 11232 13060 14229 14480 14559>,
			<11657 11304 12919 14283 14948 16302>,
			<11870 11544 13308 14855 15292 15918>,
			<11767 11607 13302 14904 16897 15912>,
			<11256 11453 13299 15479 17355 16145>,
			<10638 11362 13369 16782 17681 18092>,
			<10215 11037 13599 16662 17664 18168>,
			<10215 11037 13599 16662 17664 18168>,
			<10215 11037 13599 16662 17664 18168>;
	};

	qcom,pc-temp-y6-lut {
		qcom,lut-col-legend = <(-10) 0 10 25 40 50>;
		qcom,lut-row-legend = <10000 9800 9600 9400 9200 9000>,
			<8800 8600 8400 8200 8000 7800>,
			<7600 7400 7200 7000 6800 6600>,
			<6400 6200 6000 5800 5600 5400>,
			<5200 5000 4800 4600 4400 4200>,
			<4000 3800 3600 3400 3200 3000>,
			<2800 2600 2400 2200 2000 1800>,
			<1600 1400 1200 1000 900 800>,
			<700 600 500 400 300 200>,
			<100 0>;
		qcom,lut-data = <6533 5656 5250 5057 5006 4993>,
			<6630 5660 5249 5057 5006 4993>,
			<6692 5665 5249 5057 5006 4993>,
			<6726 5670 5249 5057 5007 4994>,
			<6741 5675 5249 5058 5008 4995>,
			<6744 5678 5249 5060 5009 4996>,
			<6719 5679 5251 5061 5010 4997>,
			<6678 5679 5254 5063 5011 4998>,
			<6677 5684 5256 5065 5013 4999>,
			<6731 5705 5258 5067 5014 5001>,
			<6772 5720 5260 5070 5016 5003>,
			<6668 5710 5277 5076 5020 5004>,
			<6477 5688 5302 5083 5025 5006>,
			<6421 5665 5304 5086 5029 5009>,
			<6414 5631 5287 5087 5031 5012>,
			<6410 5610 5275 5089 5034 5015>,
			<6415 5615 5281 5100 5039 5019>,
			<6423 5627 5292 5114 5044 5023>,
			<6414 5628 5289 5116 5046 5025>,
			<6323 5606 5261 5111 5047 5027>,
			<6242 5580 5234 5104 5047 5029>,
			<6244 5564 5221 5084 5033 5018>,
			<6285 5549 5211 5059 5013 5001>,
			<6342 5534 5208 5053 5007 4996>,
			<6471 5516 5206 5052 5006 4995>,
			<6615 5499 5205 5052 5006 4995>,
			<6712 5477 5206 5052 5006 4995>,
			<6792 5451 5209 5055 5008 4997>,
			<6860 5449 5209 5057 5010 4999>,
			<6917 5509 5202 5061 5013 5001>,
			<6968 5587 5197 5065 5017 5004>,
			<7014 5642 5197 5069 5022 5008>,
			<7056 5693 5198 5072 5026 5012>,
			<7098 5741 5201 5073 5027 5013>,
			<7141 5785 5221 5070 5024 5009>,
			<7183 5827 5243 5068 5020 5005>,
			<7227 5869 5258 5066 5014 5001>,
			<7273 5910 5271 5064 5009 4997>,
			<7316 5955 5284 5064 5008 4996>,
			<7356 6005 5295 5066 5012 4998>,
			<7396 6060 5308 5067 5014 4999>,
			<7442 6121 5322 5069 5014 4999>,
			<7495 6192 5338 5070 5014 4999>,
			<7566 6273 5357 5071 5011 4997>,
			<7655 6371 5375 5072 5010 4997>,
			<7680 6392 5340 5068 5016 5002>,
			<7589 6346 5345 5074 5019 5004>,
			<7708 6437 5364 5078 5022 5008>,
			<7830 6548 5399 5086 5027 5016>,
			<7952 6648 5437 5091 5025 5010>,
			<8105 6737 5439 5082 5020 5004>,
			<8420 6889 5477 5091 5024 5007>,
			<9048 7172 5550 5110 5033 5017>,
			<9852 7607 5652 5140 5055 5039>,
			<9852 7607 5652 5140 5055 5039>,
			<9852 7607 5652 5140 5055 5039>;
	};

};
